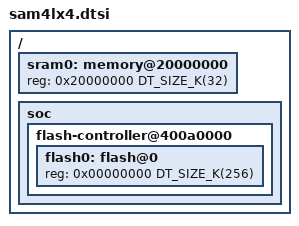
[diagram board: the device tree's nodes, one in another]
/*
 * Copyright (c) 2020 Gerson Fernando Budke <nandojve@gmail.com>
 *
 * SPDX-License-Identifier: Apache-2.0
 */

#include <mem.h>
#include <atmel/sam4l.dtsi>

/ {
	sram0: memory@20000000 {
		reg = <0x20000000 DT_SIZE_K(32)>;
	};

	soc {
		flash-controller@400a0000 {
			flash0: flash@0 {
				reg = <0x00000000 DT_SIZE_K(256)>;
			};
		};
	};
};
